# SC32F10T_10G register map
File version: 1.0
CPU: CM0+ r0p1, little endian, MPU, no FPU, 4 interrupt priority bits
Registers are 32-bit, read-write, reset 0x0 unless marked. A register's access mark holds for its fields unless they carry their own. Offsets are from the block's base; [hi:lo] are bit positions; <NAME> marks a mode.

## IAP
Base 0x400003C0
0x00 IAP_KEY — 数据保护寄存器
  [31:0] IAPKEY — 数据保护锁为防止因电气干扰等原因出现对Flash的意外操作，IAP_CON寄存器执行写操作前需要通过IAPKEY解锁。解锁顺序如下：写入 KEY1 = 0x1234_5678写入 KEY2 = 0xA05F_05FA如果操作顺序不正确，会锁定 IAP_CON 寄存器，直到下次系统复位才会解锁。
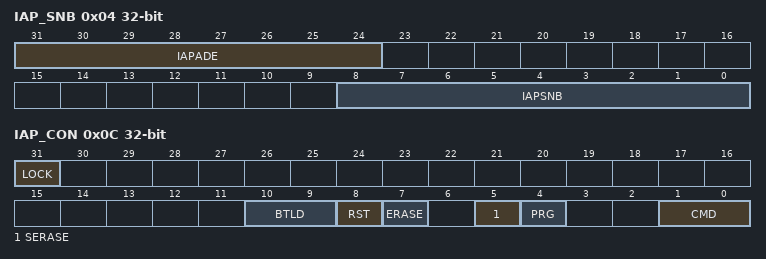
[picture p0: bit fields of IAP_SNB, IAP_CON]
0x04 IAP_SNB — IAP扇区编号设置寄存器
  [31:24] IAPADE — IAP操作区域扩展地址通过向IAPADE写入不同的值，使得IAP操作指向不同的操作区域：0x00：无效0x4C：APROM其它：保留
  [8:0] IAPSNB — 扇擦/页擦时的IAP 操作扇区编号设置：实际操作扇区的起始地址= Flash 基址 + [ STARTB[8:0] x 0x200 ]
0x0C IAP_CON — IAP控制寄存器
  [31] LOCK — 对该位写1后，IAP_CON 寄存器被锁定。当检测到解锁序列时，由硬件将该位清0。如果解锁操作失败，该位仍保持置 1，直到下一次系统复位。
  [10:9] BTLD — 软件复位后程序启动区域选择位：00：芯片软件复位后从APROM（主存储区）启动01：芯片软件复位后从LDROM（系统存储区）启动10：芯片软件复位后从嵌入式SRAM启动11：保留
  [8] RST — 软件复位控制位0：程序正常运行1：对该位写1后系统立刻复位
  [7] ERASE — 全擦（All Erase）控制位0：无操作1：对该位写1后再配置CMD[1:0]=10，则进入APROM全擦除操作，APROM将全部擦除
  [5] SERASE — 扇区擦除（Sector Erase）控制位0：无操作1：对该位写1后再配置CMD[1:0]=10，则进入APROM扇区擦除操作，APROM的指定Sector将被擦除
  [4] PRG — 编程（Program）控制位0：禁止 Flash 编程1：使能 Flash 编程
  [1:0] CMD — IAP命令使能控制位10：执行擦除操作命令其它 : 保留注意：擦除操作命令位写1后，必须配置CMD[1:0]=10，相应的操作才会开始执行一次只能执行1种IAP操作，所以ERASE/SERASE位同一时间只能有一位置1

## RCC
Base 0x40003000
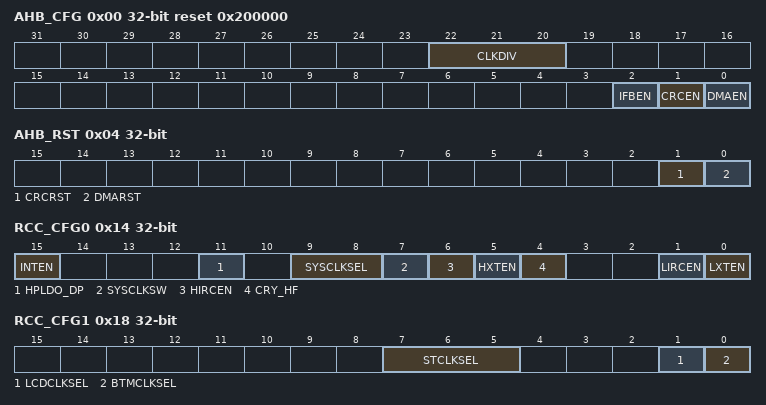
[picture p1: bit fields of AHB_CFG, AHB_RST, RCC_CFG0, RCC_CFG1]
0x00 AHB_CFG reset 0x200000 — AHB总线外设时钟使能寄存器
  [22:20] CLKDIV — AHB时钟分频设置位AHB总线时钟HCLK来自系统时钟SYSCLK的分频：000: fHCLK= fSYSCLK001: fHCLK= fSYSCLK / 2010: fHCLK= fSYSCLK / 4011: fHCLK= fSYSCLK / 8100: fHCLK= fSYSCLK / 16其它：保留
  [2] IFBEN — Customer Option映射寄存器时钟使能位使用OPINX配合OPREG改写IFB映射寄存器之前，应先要打开时钟使能。 0：禁止1：使能
  [1] CRCEN — CRC模块时钟使能位0：禁止1：使能
  [0] DMAEN — DMA时钟使能位0：禁止1：使能
0x04 AHB_RST — AHB总线外设复位控制寄存器
  [1] CRCRST — CRC复位控制位该位通过软件写1，由硬件自动清0。0：无影响1：复位RCC
  [0] DMARST — DMA复位控制位该位通过软件写1，由硬件自动清0。0：无影响1：复位DMA
0x0C RCC_KEY — RCC保护寄存器
  [7:0] RCCKEY — RCC_CFG0、RCC_CFG1、PLL_CFG这三个寄存器的操作使能开关及时限设置。写入一个大于等于0x40的值n，代表：打开RCC_CFG0、RCC_CFG1、PLL_CFG这三个寄存器的写操作功能；n个系统时钟后如果接收不到寄存器写入命令，则RCC改写功能被重新关闭。
0x14 RCC_CFG0 — 系统时钟源选择寄存器
  [15] INTEN — 中断请求 CPU的使能控制位 0：禁止中断请求 1：使能中断请求
  [11] HPLDO_DP — 低频系统时钟功耗调整位0：系统时钟源非LIRC推荐设置。1：系统时钟源选择LIRC推荐设置。当系统时钟选择LIRC，此位写1可降低整体功耗
  [9:8] SYSCLKSEL — 系统时钟源选择位00：系统时钟源来自LIRC01：系统时钟源来自HXT10：系统时钟源来自PLLR11：系统时钟源来自LXT注意：上电默认的系统时钟源为HIRC，用户可在上电后的正常操作阶段，通过软件方式切换时钟源。切换前务必确保所选时钟源已处于稳定的工作状态；系统时钟源无论选择切换至哪一种，都必须先将系统时钟源切换至HIRC，再切换至目标时钟源。
  [7] SYSCLKSW — 系统时钟源切换位，使能后系统时钟源从HIRC切换至SYSCLKSEL所选的时钟：0：系统时钟源为HIRC1：系统时钟源为SYSCLKSEL设置项对此位改写后，必须内部电路切换成功才会更新改写的值，否则读到的一直是改写前的状态。用户可以通过读取此位的方式判断时钟源是否已切换成功。复位/唤醒后此位将自动清零，即复位/唤醒后由HIRC提供系统时钟。注意：上电默认的系统时钟源为HIRC，用户可在上电后的正
  [6] HIRCEN — 内建高频32MHz振荡器HIRC使能位0：禁止1：使能当SYSCLKSW = 0，选择HIRC作为系统时钟时，此位不可写入。复位/唤醒后此位将由硬件置1，即复位/唤醒后由HIRC提供系统时钟。
  [5] HXTEN — 外接高频晶振HXT使能位0：禁止1：使能复位/唤醒后此位将自动清零。
  [4] CRY_HF — 外接高频晶振HXT振荡频率范围选择位0：外接晶振振荡频率<12M1：外接晶振振荡频率≥12M
  [1] LIRCEN — 内建低频32kHz振荡器LIRC使能位0：禁止1：使能
  [0] LXTEN — 外接低频晶振LXT使能位0：禁止1：使能
0x18 RCC_CFG1 — 外设时钟源选择寄存器
  [7:5] STCLKSEL — SysTick时钟源选择位000：时钟源来自HCLK/8001：时钟源来自HIRC/2010：时钟源来自HXT/2011：时钟源来自LIRC100：时钟源来自LXT注意：用户配置时注意，如果 SysTick时钟源不是来自HCLK，SysTick时钟源频率必须小于或等于fHCLK/2。
  [1] LCDCLKSEL — LCD时钟源选择位0：时钟源来自LIRC1：时钟源来自LXT对此位改写后，必须等待内部电路切换成功才会更新改写的值，否则读到的一直是改写前的状态。用户可以通过读取此位的方式判断时钟源是否已切换成功。
  [0] BTMCLKSEL — BTM时钟源选择位0：时钟源来自LIRC1：时钟源来自LXT对此位改写后，必须等待内部电路切换成功才会更新改写的值，否则读到的一直是改写前的状态。用户可以通过读取此位的方式判断时钟源是否已切换成功。
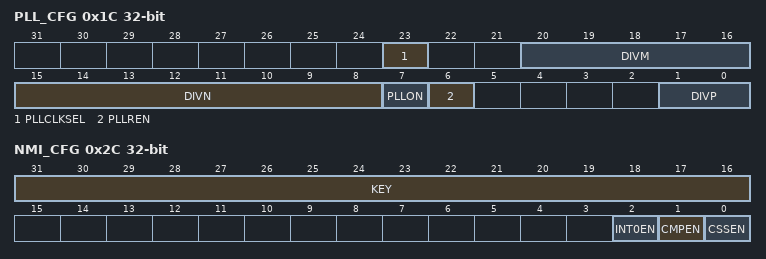
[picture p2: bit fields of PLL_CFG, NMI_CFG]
0x1C PLL_CFG — PLL配置寄存器
  [23] PLLCLKSEL — PLL时钟源选择位1：PLL时钟源来自外部高速晶振 HXT，PLL输入时钟的频率fPLL_IN = fHXT0：PLL时钟源来自内部高速震荡时钟 HIRC，PLL输入时钟的频率fPLL_IN = fHIRC注意：只有在禁止 PLL 时才能写入此位域。
  [20:16] DIVM — PLL时钟源预分频有效值：0x01~0x1F注意：用户需自行配置保证PLL输入频率分至2MHz。
  [15:8] DIVN — PLL倍频系数2 <= N <=192 0x00、0x01及大于192的值：无效计算公式：fPLLR = [ ( fPLL_IN / DIVM ) * DIVN ] / 2 ^ ( DIVP +1 )注意：用户需自行配置保证倍频后频率保持在200MHz ~ 400MHz之间, 之后用户需自行配置DIVP分频保证输出频率PLLR不高于64MHz， PLLR可作为系统时钟源。
  [7] PLLON — PLL使能位0：PLL关闭1：PLL使能当进入停止、待机或关断模式时由硬件清零。注意：如果 PLL 时钟用作系统时钟，则此位不可为0。
  [6] PLLREN — PLLRCLK 时钟输出使能位0：禁止1：使能选择 PLL 的 PLLRCLK 输出作为系统时钟时，此位不可写入。
  [1:0] DIVP — PLLRCLK 时钟输出分频系数00：2分频01：4分频10：8分频11：16分频只有在禁止 PLL 时才能写入此位域。可选择 PLLRCLK 时钟作为系统时钟。
0x20 RCC_STS ro — 时钟状态寄存器
  [0] PLLRDY — PLL 时钟就绪标志位该位只读，由硬件置 1，用于指示 PLL 已锁定。0：PLL 未锁定1：PLL 已锁定
0x28 SYST_CALIB — SysTick校准参数寄存器
  [7:0] CALIB — 校准寄存器默认值：若，上电默认时钟为fHCLK/n（MHz），n是上电默认分频系数，上电默认时钟源为HIRC则，SysTick 校准值初始值为1000*（fHCLK/n），即保证默认可产生1ms时间基准
0x2C NMI_CFG — NMI中断配置寄存器
  [31:16] KEY — NMI_CFG寄存器写保护开关向KEY[15:0]写入 0xA05F解锁后才能对当前寄存器的低位进行改写操作。
  [2] INT0EN — 外部中断INT0非屏蔽中断源使能位0：INT0禁止触发NMI1：INT0非屏蔽中断源使能使能后，INT0口上的上升/下降沿中断均会触发NMI，手动清除相应标志位后方可退出NMI中断。注意：若INT0中断已使能，仍会优先处理NMI。
  [1] CMPEN — 比较器非屏蔽中断源使能位0：CMP禁止触发NMI1：CMP非屏蔽中断源使能使能后，CMPIF置起时会触发NMI，手动清除CMPIF标志后方可退出NMI中断。注意：如果CMP中断使能已开启（CMPCFG->CMPIM[1:0]=1），仍会优先处理NMI。
  [0] CSSEN — 时钟安全系统非屏蔽中断源使能位0：CSS禁止触发NMI1：CSS系统非屏蔽中断源使能使能后，CLKFIF置起时会触发NMI，复位后可清除CLKFIF标志。注意：如果RCC中断使能已开启（RCC_CFG0.INTEN=1），仍会优先处理NMI。
